VERSION ""

NS_ :

BS_: 500

BU_: Vector__XXX

BO_ 165 MSG_0A5: 8 Vector__XXX
 SG_ Engine_Speed : 40|16@1+ (0.25,0) [0|65535] "rpm" Vector__XXX

BO_ 217 MSG_0D9: 8 Vector__XXX
 SG_ Accelerator_Pedal_Position : 16|12@1+ (0.025,0) [0|100] "%" Vector__XXX

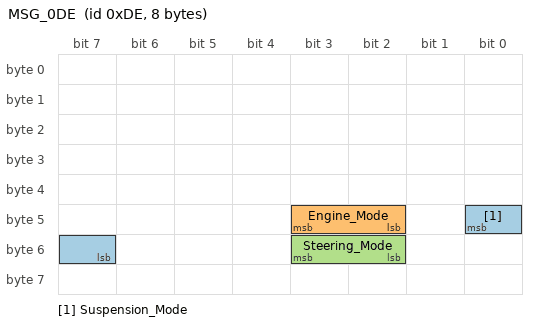
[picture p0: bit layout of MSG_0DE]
BO_ 222 MSG_0DE: 8 Vector__XXX
 SG_ Suspension_Mode : 40|2@0+ (1,0) [0|3] "" Vector__XXX
 SG_ Engine_Mode : 43|2@0+ (1,0) [0|3] "" Vector__XXX
 SG_ Steering_Mode : 51|2@0+ (1,0) [0|3] "" Vector__XXX

BO_ 239 MSG_0EF: 8 Vector__XXX
 SG_ Brake_Position : 40|16@1+ (-0.005,160) [0|100] "%" Vector__XXX

BO_ 243 MSG_0F3: 8 Vector__XXX
 SG_ Gear : 16|4@0+ (1,-4) [0|15] "" Vector__XXX

BO_ 519 MSG_207: 2 Vector__XXX
 SG_ Gear_Requested : 52|2@0+ (1,0) [0|3] "" Vector__XXX

BO_ 596 MSG_254: 8 Vector__XXX
 SG_ Wheel_Speed_RL_kph : 0|15@1- (0.02,0) [0|1000] "km/h" Vector__XXX
 SG_ Wheel_Speed_RL_mph : 0|15@1- (0.01242,0) [0|621] "mph" Vector__XXX
 SG_ Wheel_Speed_RR_kph : 16|15@1- (0.02,0) [0|32767] "km/h" Vector__XXX
 SG_ Wheel_Speed_RR_mph : 16|15@1- (0.01242,0) [0|20348.307] "mph" Vector__XXX
 SG_ Wheel_Speed_FL_kph : 32|15@1- (0.02,0) [0|500] "km/h" Vector__XXX
 SG_ Wheel_Speed_FL_mph : 32|15@1- (0.01242,0) [0|310.5] "mph" Vector__XXX
 SG_ Wheel_Speed_FR_kph : 48|15@1- (0.02,0) [0|500] "km/h" Vector__XXX
 SG_ Wheel_Speed_FR_mph : 48|15@1- (0.01242,0) [0|310.5] "mph" Vector__XXX

BO_ 609 MSG_261: 8 Vector__XXX
 SG_ Seat_Belt___Driver : 40|1@0+ (1,0) [0|1] "" Vector__XXX

BO_ 770 MSG_302: 7 Vector__XXX
 SG_ Steering_Angle : 16|16@1+ (-0.0383,1256) [-540|540] "��" Vector__XXX

BO_ 1021 MSG_3FD: 5 Vector__XXX
 SG_ Gear_Switch : 45|3@0+ (1,0) [0|7] "" Vector__XXX
